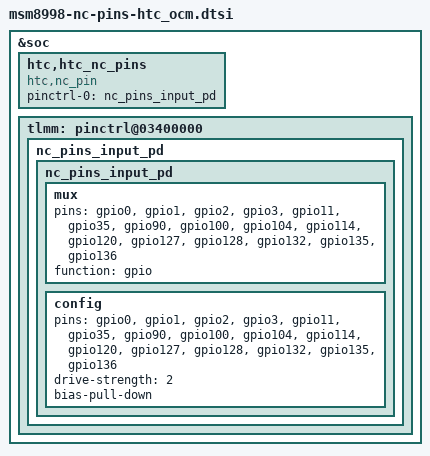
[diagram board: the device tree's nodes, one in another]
/* Copyright (c) 2016, The Linux Foundation. All rights reserved.
 *
 * This program is free software; you can redistribute it and/or modify
 * it under the terms of the GNU General Public License version 2 and
 * only version 2 as published by the Free Software Foundation.
 *
 * This program is distributed in the hope that it will be useful,
 * but WITHOUT ANY WARRANTY; without even the implied warranty of
 * MERCHANTABILITY or FITNESS FOR A PARTICULAR PURPOSE.  See the
 * GNU General Public License for more details.
 */

&soc {
	htc,htc_nc_pins {
		compatible = "htc,nc_pin";

		pinctrl-names = "default";
		pinctrl-0 = <&nc_pins_input_pd>;
	};
};

&tlmm {
	nc_pins_input_pd {
		nc_pins_input_pd: nc_pins_input_pd {
			mux {
				pins = "gpio0", "gpio1", "gpio2", "gpio3", "gpio11", "gpio35", "gpio90", "gpio100", "gpio104", "gpio114", "gpio120", "gpio127", "gpio128", "gpio132", "gpio135", "gpio136";
				function = "gpio";
			};

			config {
				pins = "gpio0", "gpio1","gpio2", "gpio3", "gpio11", "gpio35", "gpio90", "gpio100", "gpio104", "gpio114", "gpio120", "gpio127", "gpio128", "gpio132", "gpio135", "gpio136";
				drive-strength = <2>;		/* 2 mA */
				bias-pull-down;     /* PULL DOWN */
			};
		};
	};
};

&soc {
	tlmm: pinctrl@03400000 {
	};
};

